# STM32H747ZIY6@M7 register map
File version: 1.0
Registers are 32-bit, access not given, reset 0x0 unless marked. A register's access mark holds for its fields unless they carry their own. Offsets are from the block's base; [hi:lo] are bit positions; {n}, {i} and the like mark numbered series.

## DSI
Base 0x50000000
0x00 VR
0x04 CR
  [0] EN
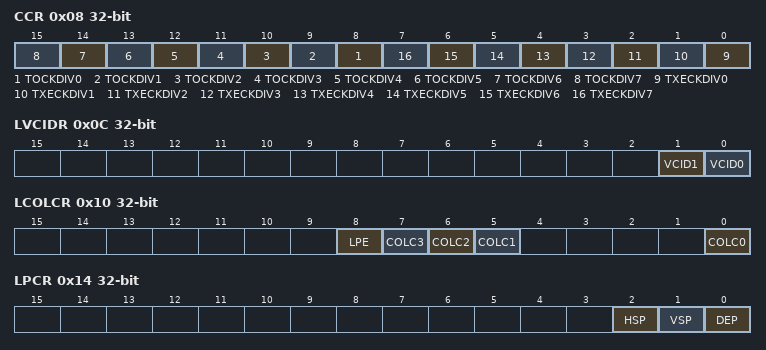
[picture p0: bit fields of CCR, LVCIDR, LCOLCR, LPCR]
0x08 CCR
  [n+8] TOCKDIV{n} (n=0..7), [n] TXECKDIV{n} (n=0..7)
0x0C LVCIDR
  [1] VCID1, [0] VCID0
0x10 LCOLCR
  [8] LPE, [7] COLC3, [6] COLC2, [5] COLC1, [0] COLC0
0x14 LPCR
  [2] HSP, [1] VSP, [0] DEP
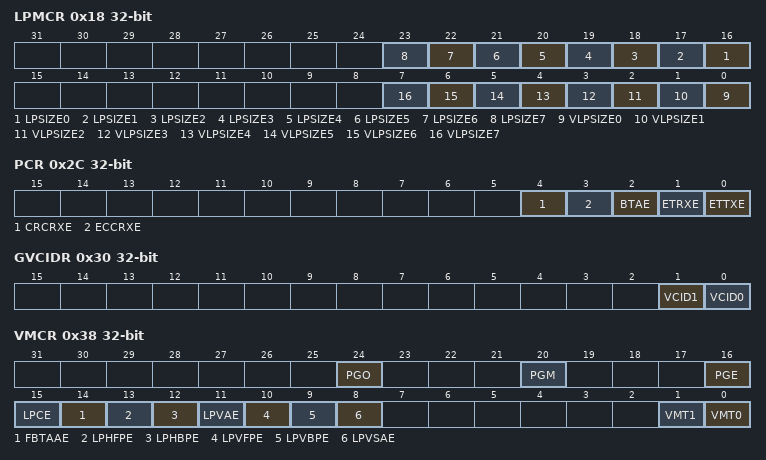
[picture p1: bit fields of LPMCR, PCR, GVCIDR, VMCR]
0x18 LPMCR
  [n+16] LPSIZE{n} (n=0..7), [n] VLPSIZE{n} (n=0..7)
0x2C PCR
  [4] CRCRXE, [3] ECCRXE, [2] BTAE, [1] ETRXE, [0] ETTXE
0x30 GVCIDR
  [1] VCID1, [0] VCID0
0x34 MCR
  [0] CMDM
0x38 VMCR
  [24] PGO, [20] PGM, [16] PGE, [15] LPCE, [14] FBTAAE, [13] LPHFPE, [12] LPHBPE, [11] LPVAE, [10] LPVFPE, [9] LPVBPE, [8] LPVSAE, [1] VMT1, [0] VMT0
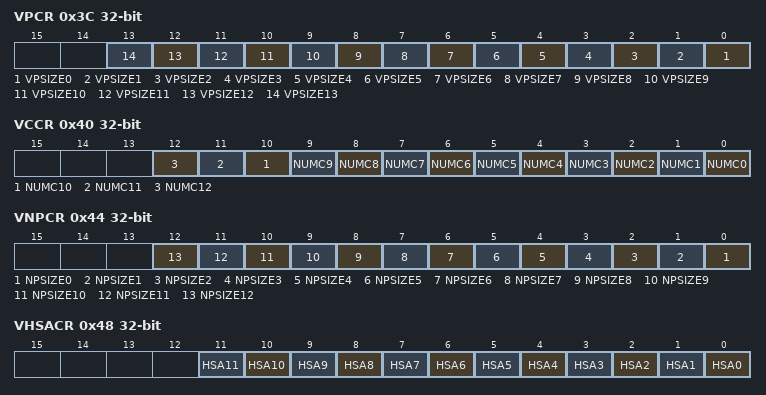
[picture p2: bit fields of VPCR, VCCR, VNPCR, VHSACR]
0x3C VPCR
  [n] VPSIZE{n} (n=0..13)
0x40 VCCR
  [n] NUMC{n} (n=0..12)
0x44 VNPCR
  [n] NPSIZE{n} (n=0..12)
0x48 VHSACR
  [n] HSA{n} (n=0..11)
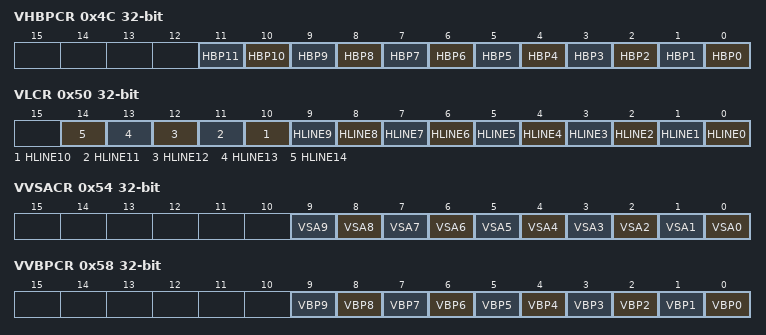
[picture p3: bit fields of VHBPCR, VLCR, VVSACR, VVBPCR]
0x4C VHBPCR
  [n] HBP{n} (n=0..11)
0x50 VLCR
  [n] HLINE{n} (n=0..14)
0x54 VVSACR
  [n] VSA{n} (n=0..9)
0x58 VVBPCR
  [n] VBP{n} (n=0..9)
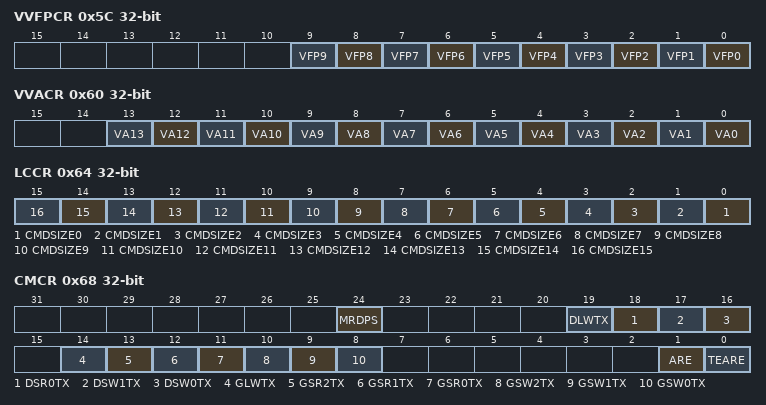
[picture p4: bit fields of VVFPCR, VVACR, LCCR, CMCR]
0x5C VVFPCR
  [n] VFP{n} (n=0..9)
0x60 VVACR
  [n] VA{n} (n=0..13)
0x64 LCCR
  [n] CMDSIZE{n} (n=0..15)
0x68 CMCR
  [24] MRDPS, [19] DLWTX, [18] DSR0TX, [17] DSW1TX, [16] DSW0TX, [14] GLWTX, [13] GSR2TX, [12] GSR1TX, [11] GSR0TX, [10] GSW2TX, [9] GSW1TX, [8] GSW0TX, [1] ARE, [0] TEARE
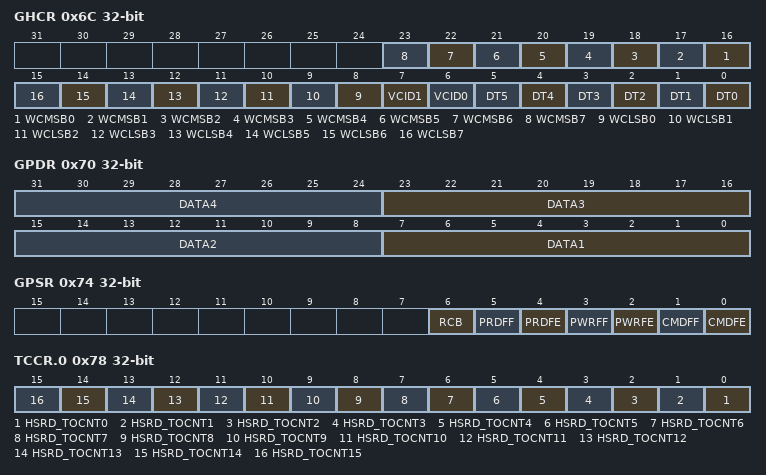
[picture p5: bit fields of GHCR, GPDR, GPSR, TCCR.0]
0x6C GHCR
  [n+16] WCMSB{n} (n=0..7), [n+8] WCLSB{n} (n=0..7), [7] VCID1, [6] VCID0, [n] DT{n} (n=0..5)
0x70 GPDR
  [8n-1:8n-8] DATA{n} (n=1..4)
0x74 GPSR
  [6] RCB, [5] PRDFF, [4] PRDFE, [3] PWRFF, [2] PWRFE, [1] CMDFF, [0] CMDFE
0x78 TCCR.0
  [n] HSRD_TOCNT{n} (n=0..15)
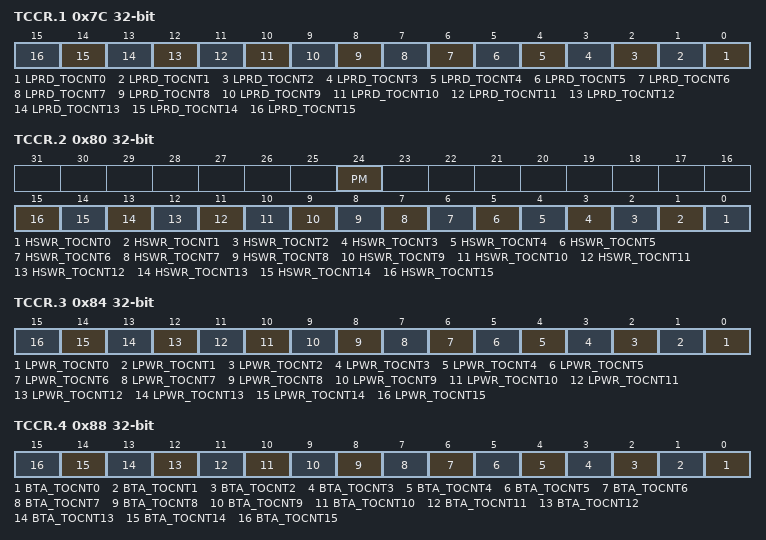
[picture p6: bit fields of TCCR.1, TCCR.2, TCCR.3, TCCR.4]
0x7C TCCR.1
  [n] LPRD_TOCNT{n} (n=0..15)
0x80 TCCR.2
  [24] PM, [n] HSWR_TOCNT{n} (n=0..15)
0x84 TCCR.3
  [n] LPWR_TOCNT{n} (n=0..15)
0x88 TCCR.4
  [n] BTA_TOCNT{n} (n=0..15)
0x8C TCCR.5
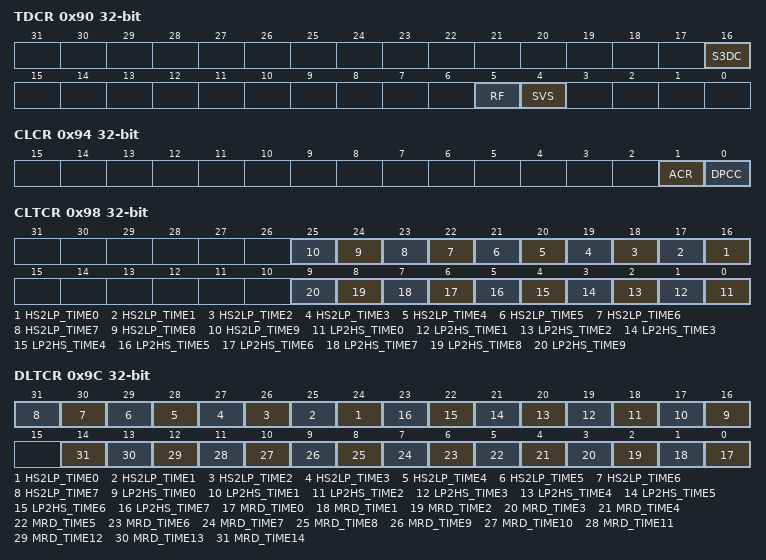
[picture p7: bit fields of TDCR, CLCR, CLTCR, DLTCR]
0x90 TDCR
  [16] S3DC, [5] RF, [4] SVS
0x94 CLCR
  [1] ACR, [0] DPCC
0x98 CLTCR
  [n+16] HS2LP_TIME{n} (n=0..9), [n] LP2HS_TIME{n} (n=0..9)
0x9C DLTCR
  [n+24] HS2LP_TIME{n} (n=0..7), [n+16] LP2HS_TIME{n} (n=0..7), [n] MRD_TIME{n} (n=0..14)
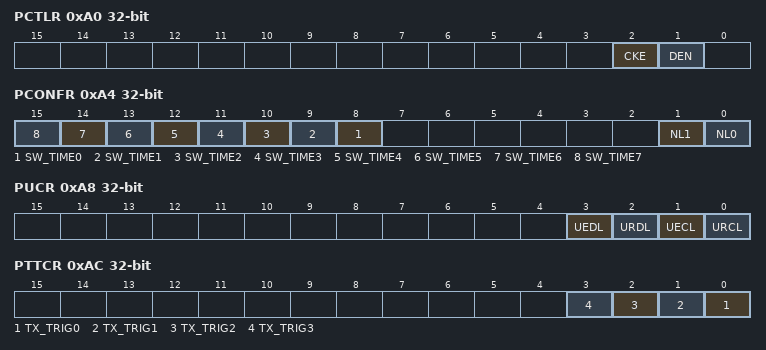
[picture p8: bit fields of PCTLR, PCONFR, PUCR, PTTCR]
0xA0 PCTLR
  [2] CKE, [1] DEN
0xA4 PCONFR
  [n+8] SW_TIME{n} (n=0..7), [1] NL1, [0] NL0
0xA8 PUCR
  [3] UEDL, [2] URDL, [1] UECL, [0] URCL
0xAC PTTCR
  [n] TX_TRIG{n} (n=0..3)
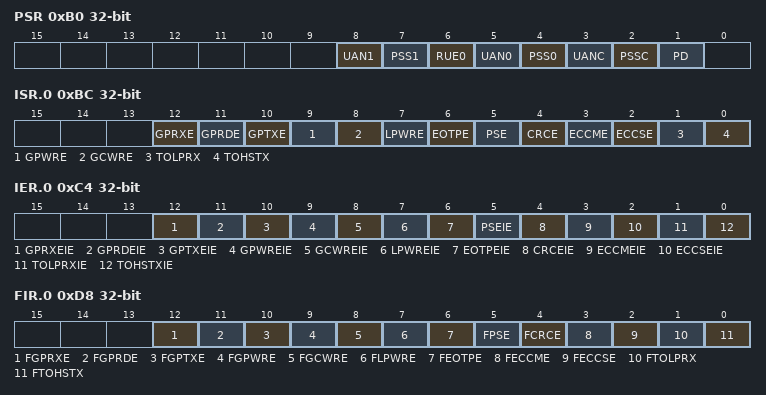
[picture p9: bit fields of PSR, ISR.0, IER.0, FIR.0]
0xB0 PSR
  [8] UAN1, [7] PSS1, [6] RUE0, [5] UAN0, [4] PSS0, [3] UANC, [2] PSSC, [1] PD
0xBC ISR.0
  [12] GPRXE, [11] GPRDE, [10] GPTXE, [9] GPWRE, [8] GCWRE, [7] LPWRE, [6] EOTPE, [5] PSE, [4] CRCE, [3] ECCME, [2] ECCSE, [1] TOLPRX, [0] TOHSTX
0xC0 ISR.1
0xC4 IER.0
  [12] GPRXEIE, [11] GPRDEIE, [10] GPTXEIE, [9] GPWREIE, [8] GCWREIE, [7] LPWREIE, [6] EOTPEIE, [5] PSEIE, [4] CRCEIE, [3] ECCMEIE, [2] ECCSEIE, [1] TOLPRXIE, [0] TOHSTXIE
0xC8 IER.1
0xD8 FIR.0
  [12] FGPRXE, [11] FGPRDE, [10] FGPTXE, [9] FGPWRE, [8] FGCWRE, [7] FLPWRE, [6] FEOTPE, [5] FPSE, [4] FCRCE, [3] FECCME, [2] FECCSE, [1] FTOLPRX, [0] FTOHSTX
0xDC FIR.1
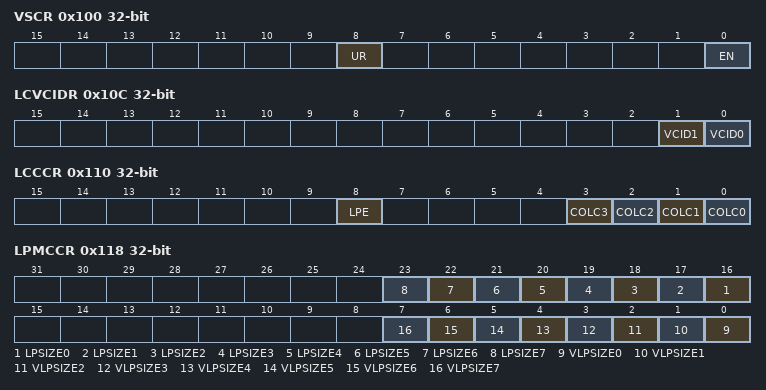
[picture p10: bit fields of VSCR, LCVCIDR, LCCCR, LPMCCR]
0x100 VSCR
  [8] UR, [0] EN
0x10C LCVCIDR
  [1] VCID1, [0] VCID0
0x110 LCCCR
  [8] LPE, [n] COLC{n} (n=0..3)
0x118 LPMCCR
  [n+16] LPSIZE{n} (n=0..7), [n] VLPSIZE{n} (n=0..7)
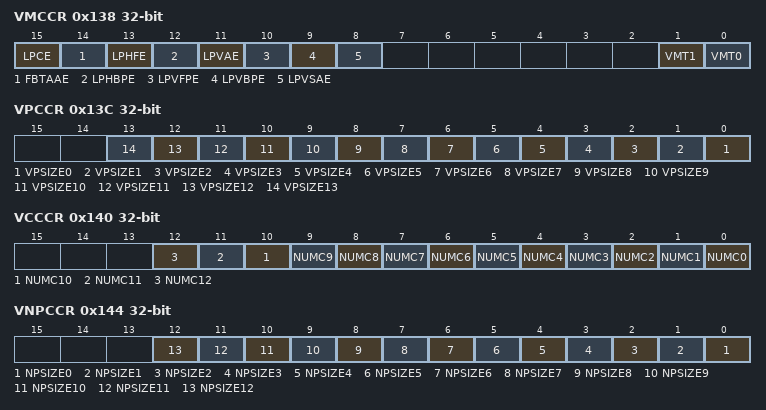
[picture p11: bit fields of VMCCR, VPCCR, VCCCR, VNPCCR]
0x138 VMCCR
  [15] LPCE, [14] FBTAAE, [13] LPHFE, [12] LPHBPE, [11] LPVAE, [10] LPVFPE, [9] LPVBPE, [8] LPVSAE, [1] VMT1, [0] VMT0
0x13C VPCCR
  [n] VPSIZE{n} (n=0..13)
0x140 VCCCR
  [n] NUMC{n} (n=0..12)
0x144 VNPCCR
  [n] NPSIZE{n} (n=0..12)
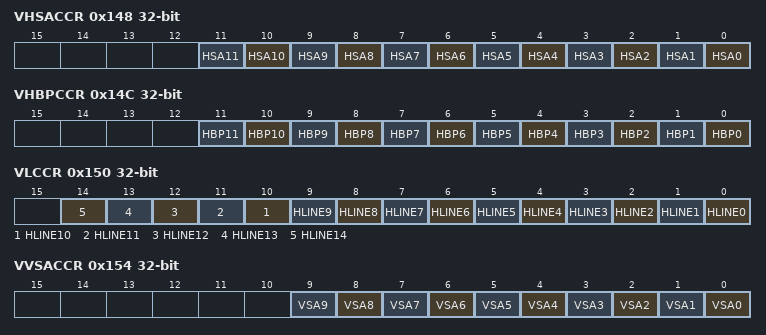
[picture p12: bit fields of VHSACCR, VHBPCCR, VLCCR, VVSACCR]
0x148 VHSACCR
  [n] HSA{n} (n=0..11)
0x14C VHBPCCR
  [n] HBP{n} (n=0..11)
0x150 VLCCR
  [n] HLINE{n} (n=0..14)
0x154 VVSACCR
  [n] VSA{n} (n=0..9)
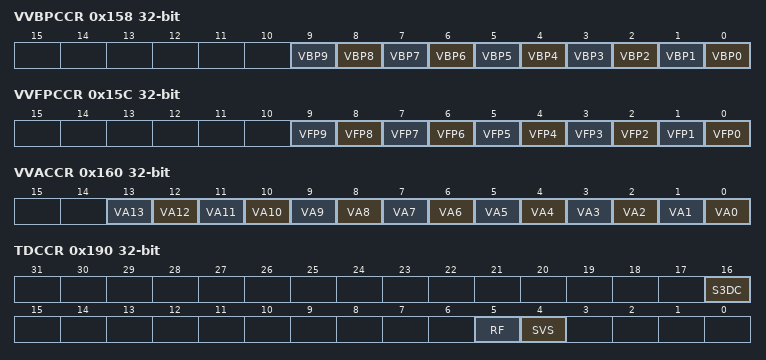
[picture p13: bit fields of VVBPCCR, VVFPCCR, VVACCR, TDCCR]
0x158 VVBPCCR
  [n] VBP{n} (n=0..9)
0x15C VVFPCCR
  [n] VFP{n} (n=0..9)
0x160 VVACCR
  [n] VA{n} (n=0..13)
0x190 TDCCR
  [16] S3DC, [5] RF, [4] SVS
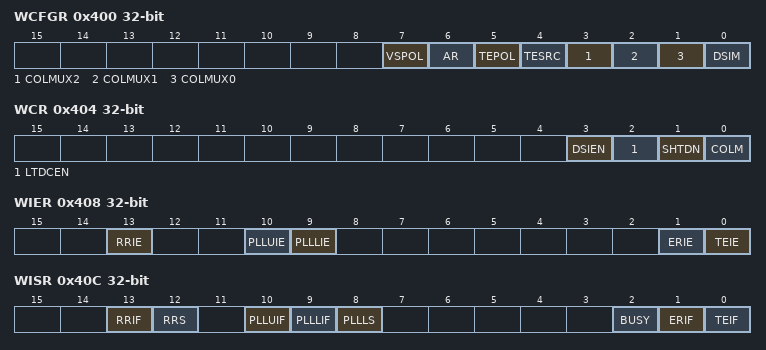
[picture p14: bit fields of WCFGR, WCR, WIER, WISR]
0x400 WCFGR
  [7] VSPOL, [6] AR, [5] TEPOL, [4] TESRC, [3] COLMUX2, [2] COLMUX1, [1] COLMUX0, [0] DSIM
0x404 WCR
  [3] DSIEN, [2] LTDCEN, [1] SHTDN, [0] COLM
0x408 WIER
  [13] RRIE, [10] PLLUIE, [9] PLLLIE, [1] ERIE, [0] TEIE
0x40C WISR
  [13] RRIF, [12] RRS, [10] PLLUIF, [9] PLLLIF, [8] PLLLS, [2] BUSY, [1] ERIF, [0] TEIF
0x410 WIFCR
  [13] CRRIF, [10] CPLLUIF, [9] CPLLLIF, [1] CERIF, [0] CTEIF
0x418 WPCR.0
  [26] LPRXFT1, [25] LPRXFT0, [22] FLPRXLPM, [19] HSTXSRCDL1, [18] HSTXSRCDL0, [17] HSTXSRCCL1, [16] HSTXSRCCL0, [15] LPRXVCDL1, [14] LPRXVCDL0, [12] SDDC, [9] LPSRCDL1, [8] LPSRCDL0, [7] LPSRCCL1, [6] LPSRCCL0, [3] HSTXDDL1, [2] HSTXDDL0, [1] HSTXDCL1, [0] HSTXDCL0
0x41C WPCR.1
  [n+24] THSTRAIL{n} (n=0..7), [n+16] THSPREP{n} (n=0..7), [n+8] TCLKZERO{n} (n=0..7), [n] TCLKPREP{n} (n=0..7)
0x420 WPCR.2
  [n+24] TLPXC{n} (n=0..7), [n+16] THSEXIT{n} (n=0..7), [n+8] TLPXD{n} (n=0..7), [n] THSZERO{n} (n=0..7)
0x424 WPCR.3
  [n] TCLKPOST{n} (n=0..7)
0x428 WPCR.4
0x430 WRPCR
  [24] REGEN, [17] PLL_ODF1, [16] PLL_ODF0, [n+11] PLL_IDF{n} (n=0..3), [n+2] PLL_NDIV{n} (n=0..6), [0] PLLEN
